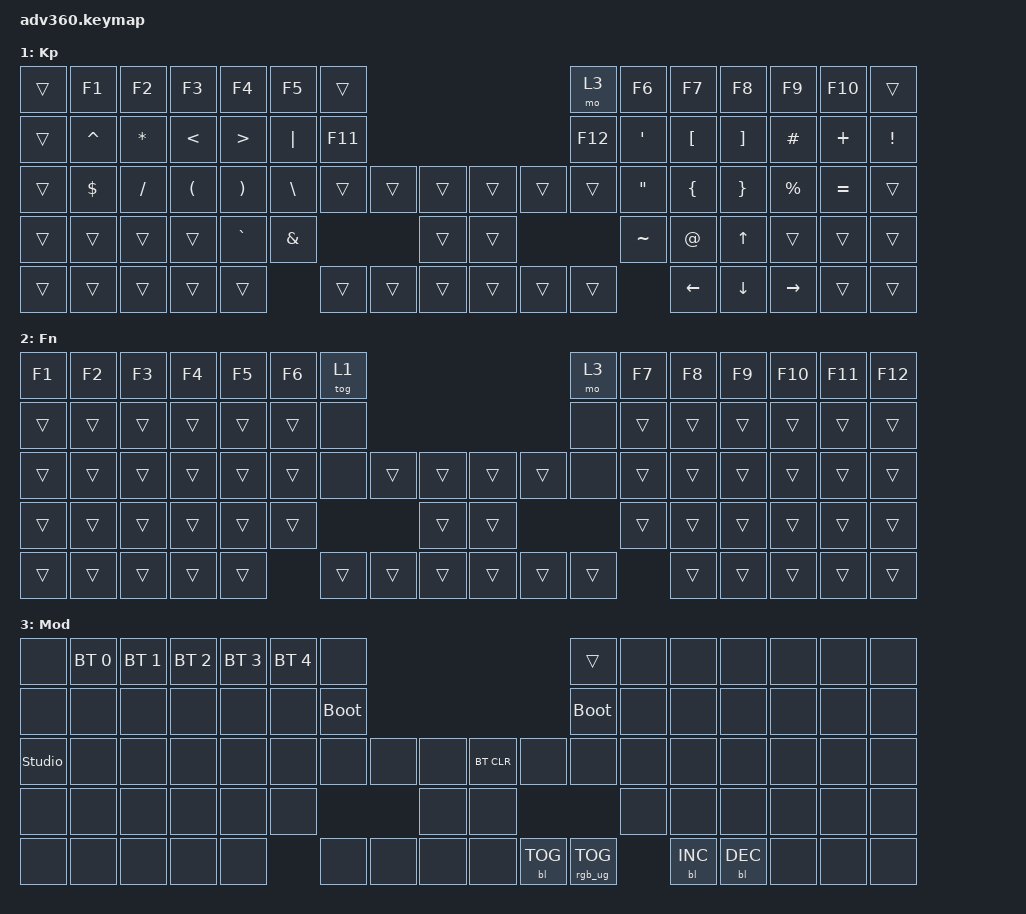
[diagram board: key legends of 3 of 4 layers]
#include <dt-bindings/zmk/stp.h>
#include <dt-bindings/zmk/backlight.h>
#include <dt-bindings/zmk/bt.h>
#include <dt-bindings/zmk/keys.h>
#include <dt-bindings/zmk/rgb.h>
#include <behaviors.dtsi>
#include "behaviors.dtsi"
#include "macros.dtsi"

/ {
  behaviors {
    #include "version.dtsi"
    hm: homerow_mods {
      compatible = "zmk,behavior-hold-tap";
      label = "HOMEROW_MODS";
      #binding-cells = <2>;
      tapping-term-ms = <200>;
      quick_tap_ms = <200>;
      flavor = "tap-preferred";
      bindings = <&kp>, <&kp>;
    };
  };

  keymap {
    compatible = "zmk,keymap";

    default_layer {
      display-name = "Base";
      bindings = <
        &kp ESC           &kp N1    &kp N2    &kp N3        &kp N4  &kp N5  &none                                                     &mo 3    &kp N6  &kp N7  &kp N8             &kp N9    &kp N0     &kp QUESTION
        &kp TAB           &kp Q     &kp W     &kp E         &kp R   &kp T   &none                                                     &none    &kp Z   &kp U   &kp I              &kp O     &kp P      &umlaut_u_shifted
        &kp BACKSPACE     &hm LGUI A     &hm LALT S     &hm LSHFT D         &hm LCTRL F   &kp G   &none      &kp LCTRL  &kp LALT      &kp LGUI   &kp RCTRL  &kp DEL  &kp H   &hm RCTRL J   &hm RSHFT K              &hm RALT L     &hm RGUI &umlaut_o_shifted      &umlaut_a_shifted
        &kp LSHFT         &kp Y     &kp X     &kp C         &kp V   &kp B                         &kp HOME      &kp PG_UP                      &kp N   &kp M   &semi_shifted  &colon_shifted   &kp MINUS  &kp RSHFT
        &kp LEFT_CONTROL  &kp LALT  &kp CAPS  &kp LGUI  &mo 1           &kp SPACE  &mo 1      &kp END       &kp PG_DN  &mo 2      &kp RET          &mo 1   &kp RIGHT_CONTROL  &kp CAPS  &kp RGUI   &kp RIGHT_CONTROL
      >;
    };

    keypad {
      display-name = "Kp";
      bindings = <
        &trans  &kp F1     &kp F2     &kp F3    &kp F4     &kp F5         &trans                                       &mo 3    &kp F6     &kp F7    &kp F8             &kp F9     &kp F10    &trans
        &trans  &kp CARET  &kp ASTRK  &kp LT    &kp GT     &kp PIPE       &kp F11                                      &kp F12  &kp SQT    &kp LBKT  &kp RIGHT_BRACKET  &kp HASH   &kp PLUS   &kp EXCL
        &trans  &kp DLLR   &kp SLASH  &kp LPAR  &kp RPAR   &kp BACKSLASH  &trans   &trans  &trans      &trans  &trans  &trans   &kp DQT    &kp LBRC  &kp RBRC           &kp PRCNT  &kp EQUAL  &trans
        &trans  &trans     &trans     &trans    &kp GRAVE  &kp AMPERSAND                   &trans      &trans                   &kp TILDE  &kp AT    &kp UP             &trans     &trans     &trans
        &trans  &trans     &trans     &trans    &trans                    &trans   &trans  &trans      &trans  &trans  &trans              &kp LEFT  &kp DOWN           &kp RIGHT  &trans     &trans
      >;
    };

    fn {
      display-name = "Fn";
      bindings = <
        &kp F1  &kp F2  &kp F3  &kp F4  &kp F5  &kp F6  &tog 1                                      &mo 3   &kp F7  &kp F8  &kp F9  &kp F10  &kp F11  &kp F12
        &trans  &trans  &trans  &trans  &trans  &trans  &none                                       &none   &trans  &trans  &trans  &trans   &trans   &trans
        &trans  &trans  &trans  &trans  &trans  &trans  &none   &trans  &trans      &trans  &trans  &none   &trans  &trans  &trans  &trans   &trans   &trans
        &trans  &trans  &trans  &trans  &trans  &trans                  &trans      &trans                  &trans  &trans  &trans  &trans   &trans   &trans
        &trans  &trans  &trans  &trans  &trans          &trans  &trans  &trans      &trans  &trans  &trans          &trans  &trans  &trans   &trans   &trans
      >;
    };

    mod {
      display-name = "Mod";
      bindings = <
        &none           &bt BT_SEL 0  &bt BT_SEL 1  &bt BT_SEL 2  &bt BT_SEL 3  &bt BT_SEL 4  &none                                                  &trans           &none  &none       &none       &none  &none  &none
        &none           &none         &none         &none         &none         &none         &bootloader                                            &bootloader      &none  &none       &none       &none  &none  &none
        &studio_unlock  &none         &none         &none         &none         &none         &none        &none  &none      &bt BT_CLR  &none       &none            &none  &none       &none       &none  &none  &none
        &none           &none         &none         &none         &none         &none                             &none      &none                                    &none  &none       &none       &none  &none  &none
        &none           &none         &none         &none         &none                       &none        &none  &none      &none       &bl BL_TOG  &rgb_ug RGB_TOG         &bl BL_INC  &bl BL_DEC  &none  &none  &none
      >;
    };

    extra1 {
      display-name = "Red";
      status = "reserved";
    };

    extra2 {
      display-name = "Purple";
      status = "reserved";
    };

    extra3 {
      display-name = "Cyan";
      status = "reserved";
    };

    extra4 {
      display-name = "Yellow";
      status = "reserved";
    };
  };
};
